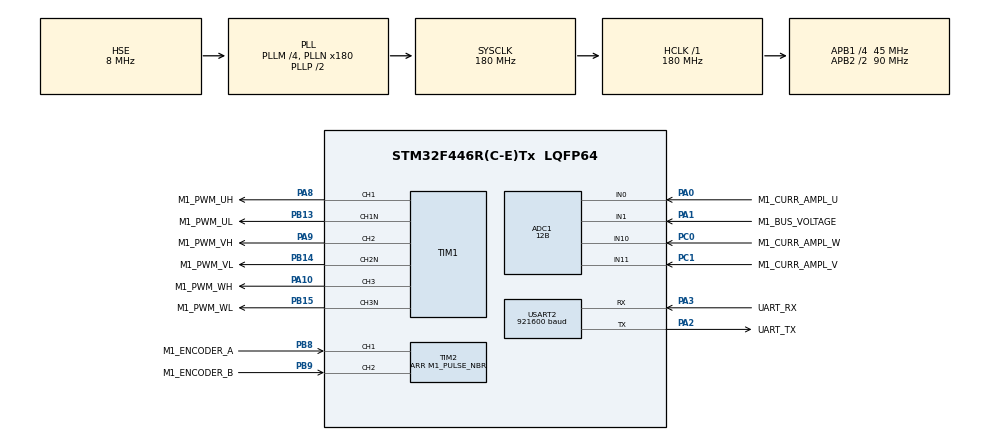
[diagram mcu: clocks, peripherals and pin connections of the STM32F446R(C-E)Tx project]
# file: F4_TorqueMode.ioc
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ADC1.Channel-1\#ChannelInjectedConversion=ADC_CHANNEL_0
ADC1.Channel-1\#ChannelRegularConversion=ADC_CHANNEL_1
ADC1.Channel-2\#ChannelInjectedConversion=ADC_CHANNEL_11
ADC1.Channel-3\#ChannelInjectedConversion=ADC_CHANNEL_10
ADC1.ClockPrescaler=ADC_CLOCK_SYNC_PCLK_DIV4
ADC1.ContinuousConvMode=DISABLE
ADC1.DMAContinuousRequests=DISABLE
ADC1.DataAlign=ADC_DATAALIGN_LEFT
ADC1.DiscontinuousConvMode=DISABLE
ADC1.EOCSelection=ADC_EOC_SINGLE_CONV
ADC1.EnableAnalogWatchDog=false
ADC1.EnableInjectedConversion=ENABLE
ADC1.EnableRegularConversion=ENABLE
ADC1.ExternalTrigConv=ADC_SOFTWARE_START
ADC1.ExternalTrigConvEdge=ADC_EXTERNALTRIGCONVEDGE_NONE
ADC1.ExternalTrigInjecConv=ADC_EXTERNALTRIGINJECCONV_T1_CC4
ADC1.ExternalTrigInjecConvEdge=ADC_EXTERNALTRIGINJECCONVEDGE_RISING
ADC1.InjNumberOfConversion=3
ADC1.InjectedConvMode=None
ADC1.InjectedOffset-1\#ChannelInjectedConversion=0
ADC1.InjectedOffset-2\#ChannelInjectedConversion=0
ADC1.InjectedOffset-3\#ChannelInjectedConversion=0
ADC1.InjectedRank-1\#ChannelInjectedConversion=1
ADC1.InjectedRank-2\#ChannelInjectedConversion=2
ADC1.InjectedRank-3\#ChannelInjectedConversion=3
ADC1.NbrOfConversion=1
ADC1.NbrOfConversionFlag=1
ADC1.Offset-1\#ChannelRegularConversion=0
ADC1.OffsetNumber-1\#ChannelRegularConversion=ADC_OFFSET_NONE
ADC1.Rank-1\#ChannelRegularConversion=1
ADC1.Resolution=ADC_RESOLUTION_12B
ADC1.SamplingTime-1\#ChannelInjectedConversion=ADC_SAMPLETIME_15CYCLES
ADC1.SamplingTime-1\#ChannelRegularConversion=ADC_SAMPLETIME_28CYCLES
ADC1.SamplingTime-2\#ChannelInjectedConversion=ADC_SAMPLETIME_15CYCLES
ADC1.SamplingTime-3\#ChannelInjectedConversion=ADC_SAMPLETIME_15CYCLES
ADC1.ScanConvMode=ENABLE
ADC1.master=1
Dma.Request0=USART2_RX
Dma.Request1=USART2_TX
Dma.USART2_RX.0.Direction=DMA_PERIPH_TO_MEMORY
Dma.USART2_RX.0.FIFOMode=DMA_FIFOMODE_DISABLE
Dma.USART2_RX.0.Instance=DMA1_Stream5
Dma.USART2_RX.0.MemDataAlignment=DMA_MDATAALIGN_BYTE
Dma.USART2_RX.0.MemInc=DMA_MINC_ENABLE
Dma.USART2_RX.0.Mode=DMA_NORMAL
Dma.USART2_RX.0.PeriphDataAlignment=DMA_PDATAALIGN_BYTE
Dma.USART2_RX.0.PeriphInc=DMA_PINC_DISABLE
Dma.USART2_RX.0.Priority=DMA_PRIORITY_LOW
Dma.USART2_TX.1.Direction=DMA_MEMORY_TO_PERIPH
Dma.USART2_TX.1.FIFOMode=DMA_FIFOMODE_DISABLE
Dma.USART2_TX.1.Instance=DMA1_Stream6
Dma.USART2_TX.1.MemDataAlignment=DMA_MDATAALIGN_BYTE
Dma.USART2_TX.1.MemInc=DMA_MINC_ENABLE
Dma.USART2_TX.1.Mode=DMA_NORMAL
Dma.USART2_TX.1.PeriphDataAlignment=DMA_PDATAALIGN_BYTE
Dma.USART2_TX.1.PeriphInc=DMA_PINC_DISABLE
Dma.USART2_TX.1.Priority=DMA_PRIORITY_LOW
ExtraMW=MotorControl
ExtraMW.MotorControl.Config=MotorControl
ExtraMW.MotorControl.Mode=MotorControl
ExtraMW.MotorControl.Root=MCSDK_v6.2.0-Full/MotorControl
ExtraMW.MotorControl.Template=templates
Mcu.Family=STM32F4
Mcu.Name=STM32F446R(C-E)Tx
Mcu.Package=LQFP64
MotorControl.ADC_AHBPERIPH=RCC_AHBPeriph_ADC1
MotorControl.ADC_CLOCK_WB_DIV=1
MotorControl.ADC_PERIPH=ADC1
MotorControl.ADC_REFERENCE_VOLTAGE=3.3
MotorControl.AUXILIARY_SPEED_MEASUREMENT_SELECTION=AUX_STATE_OBSERVER_CORDIC
MotorControl.AUX_STATE_OBSERVER_CORDIC=true
MotorControl.BOARD=NUCLEO-F446RE
MotorControl.BUS_VOLTAGE_READING=true
MotorControl.CCMRAM_ENABLED=false
MotorControl.CLOCK_FREQUENCY=CPU_CLK_180_MHZ
MotorControl.CLOCK_SOURCE=EXTERNAL
MotorControl.CPU_CLK_180_MHZ=true
MotorControl.CTLBOARD_NAME=NUCLEO-F446RE
MotorControl.CUBE_MX_VER=6.6.1
MotorControl.CURRENT_READING_TOPOLOGY=THREE_SHUNT
MotorControl.CURR_SAMPLING_TIME=15
MotorControl.DBG_MCU_LOAD_MEASURE=false
MotorControl.DEBUG_DAC_FUNCTIONALITY_EN=false
MotorControl.DRIVES_NUMBER_SELECTION=SINGLEDRIVE
MotorControl.DRIVE_NUMBER=1
MotorControl.DRIVE_TYPE=FOC
MotorControl.ENCODER=true
MotorControl.ENCODER_AVAILABLE=true
MotorControl.ENCODER_PPR=1024
MotorControl.ENC_A_GPIO_PIN=LL_GPIO_PIN_8
MotorControl.ENC_A_GPIO_PORT=GPIOB
MotorControl.ENC_B_GPIO_PIN=LL_GPIO_PIN_9
MotorControl.ENC_B_GPIO_PORT=GPIOB
MotorControl.ENC_ICx_FILTER=126
MotorControl.ENC_INVERT_SPEED=false
MotorControl.ENC_TIMER_SELECTION=ENC_TIM2
MotorControl.ENC_USE_CH3=false
MotorControl.EXT_CLK_8_MHZ=true
MotorControl.EXT_CLOCK_FREQUENCY=EXT_CLK_8_MHZ
MotorControl.FEEDBACK_NET_FILTERING=false
MotorControl.HALL_SENSORS_AVAILABLE=false
MotorControl.HIGH_SIDE_IDLE_STATE=false
MotorControl.HWV_CS=ThreeShunt_AmplifiedCurrents
MotorControl.HWV_PWM=DrivingHighAndLowSides
MotorControl.HW_COMPLEMENTED_LOW_SIDE=false
MotorControl.HW_DEAD_TIME_NS=1000
MotorControl.IPs=NVIC,RCC,SYS,MotorControl,ADC1,TIM1,TIM2,USART2,DMA
MotorControl.LOW_MEMORY_FOOTPRINT_REG=false
MotorControl.LOW_SIDE_IDLE_STATE=false
MotorControl.LOW_SIDE_SIGNALS_ENABLING=LS_PWM_TIMER
MotorControl.M1_ALIGNMENT_ANGLE_DEG=90
MotorControl.M1_ALIGNMENT_DURATION=700
MotorControl.M1_AMPLIFICATION_GAIN=20
MotorControl.M1_ANGC={0,0,0,0,0,0,0,0}
MotorControl.M1_AUXILIARY_SPEED_SENSOR=STO_CORDIC
MotorControl.M1_BOARD_MAX_CURRENT=15
MotorControl.M1_BUS_VOLTAGE_READING=true
MotorControl.M1_CONSTANT1_D=9205
MotorControl.M1_CONSTANT1_Q=9205
MotorControl.M1_CONSTANT2_QD=12498
MotorControl.M1_CORD_BEMF_CONSISTENCY_GAIN=64
MotorControl.M1_CORD_BEMF_CONSISTENCY_TOL=64
MotorControl.M1_CORD_F1=4096
MotorControl.M1_CORD_F2=16384
MotorControl.M1_CORD_FIFO_DEPTH_01HZ=64
MotorControl.M1_CORD_FIFO_DEPTH_DPP=64
MotorControl.M1_CORD_GAIN1=-3529
MotorControl.M1_CORD_GAIN2=1632
MotorControl.M1_CORD_MAX_ACCEL_DPPP=199
MotorControl.M1_CORD_VARIANCE_THRESHOLD=25
MotorControl.M1_CS_ADC_NUM=1
MotorControl.M1_CS_ADC_PHASE_SHARED=NONE
MotorControl.M1_CS_ADC_U=ADC1
MotorControl.M1_CS_ADC_V=ADC1
MotorControl.M1_CS_ADC_W=ADC1
MotorControl.M1_CS_CHANNEL_U=0
MotorControl.M1_CS_CHANNEL_V=11
MotorControl.M1_CS_CHANNEL_W=10
MotorControl.M1_CURRENT_AMPLIFICATION_TOPO=EXTERNAL
MotorControl.M1_CURRENT_SENSING_TOPO=THREE_SHUNT
MotorControl.M1_CURR_SAMPLING_TIME=15
MotorControl.M1_DBG_OPEN_LOOP_ENABLE=false
MotorControl.M1_DC_CURRENT_RS_MEAS=15
MotorControl.M1_DEFAULT_CONTROL_MODE=STC_TORQUE_MODE
MotorControl.M1_DEFAULT_FLUX_COMPONENT=0
MotorControl.M1_DEFAULT_TARGET_SPEED_RPM=592
MotorControl.M1_DEFAULT_TORQUE_COMPONENT=0
MotorControl.M1_DISCONTINUOUS_PWM=false
MotorControl.M1_DP_TOPOLOGY=NONE
MotorControl.M1_DRIVE_TYPE=FOC
MotorControl.M1_ENCODER_PPR=1024
MotorControl.M1_ENC_AVERAGING_FIFO_DEPTH=16
MotorControl.M1_ENC_A_GPIO_PIN=LL_GPIO_PIN_8
MotorControl.M1_ENC_A_GPIO_PORT=GPIOB
MotorControl.M1_ENC_B_GPIO_PIN=LL_GPIO_PIN_9
MotorControl.M1_ENC_B_GPIO_PORT=GPIOB
MotorControl.M1_ENC_ICx_FILTER=126
MotorControl.M1_ENC_TIMER_SELECTION=ENC_TIM2
MotorControl.M1_ENC_USE_CH3=false
MotorControl.M1_FEED_FORWARD_CURRENT_REG_ENABLING=false
MotorControl.M1_FINAL_I_ALIGNMENT=15
MotorControl.M1_FLUX_WEAKENING_ENABLING=false
MotorControl.M1_FW_KIDIV=32768
MotorControl.M1_FW_KI_GAIN=5000
MotorControl.M1_FW_KPDIV=32768
MotorControl.M1_FW_KP_GAIN=3000
MotorControl.M1_FW_VOLTAGE_REF=985
MotorControl.M1_HALL_PHASE_SHIFT=300
MotorControl.M1_HALL_SENSORS_PLACEMENT=DEGREES_120
MotorControl.M1_HIGH_SIDE_IDLE_STATE=false
MotorControl.M1_HW_DEAD_TIME_NS=1000
MotorControl.M1_ICL_ENABLED=false
MotorControl.M1_ID_DEMAG=-15
MotorControl.M1_IQMAX=15
MotorControl.M1_LDLQ_RATIO=1.000
MotorControl.M1_LOW_SIDE_IDLE_STATE=false
MotorControl.M1_LOW_SIDE_SIGNALS_ENABLING=LS_PWM_TIMER
MotorControl.M1_LS=0.00003
MotorControl.M1_MAX_APPLICATION_SPEED=6000
MotorControl.M1_MAX_MODULATION_INDEX=100
MotorControl.M1_MIN_APPLICATION_SPEED=0
MotorControl.M1_MOTOR_MAX_SPEED_RPM=6000
MotorControl.M1_MOTOR_NAME=MN5008_PlanetGears
MotorControl.M1_MOTOR_RATED_FLUX=0.024129002
MotorControl.M1_MOTOR_VOLTAGE_CONSTANT=6.9
MotorControl.M1_MTPA_ENABLING=false
MotorControl.M1_NOMINAL_BUS_VOLTAGE_V=40
MotorControl.M1_NOMINAL_CURRENT=15
MotorControl.M1_OCP_TOPOLOGY=NONE
MotorControl.M1_OFST={0,0,0,0,0,0,0,0}
MotorControl.M1_ON_OVER_VOLTAGE=TURN_OFF_PWM
MotorControl.M1_OVERMODULATION=false
MotorControl.M1_OVP_THRESHOLD_HIGH=48
MotorControl.M1_OV_VOLTAGE_PROT_ENABLING=true
MotorControl.M1_OV_VOLTAGE_THRESHOLD_V=48
MotorControl.M1_PID_FLUX_KD_DEFAULT=100
MotorControl.M1_PID_FLUX_KI_DEFAULT=1479
MotorControl.M1_PID_FLUX_KP_DEFAULT=1738
MotorControl.M1_PID_SPEED_KD_DEFAULT=0
MotorControl.M1_PID_SPEED_KI_DEFAULT=2301
MotorControl.M1_PID_SPEED_KP_DEFAULT=3447
MotorControl.M1_PID_TORQUE_KD_DEFAULT=100
MotorControl.M1_PID_TORQUE_KI_DEFAULT=1479
MotorControl.M1_PID_TORQUE_KP_DEFAULT=1738
MotorControl.M1_POLE_PAIR_NUM=14
MotorControl.M1_POSITION_CTRL_ENABLING=false
MotorControl.M1_POTENTIOMETER_ENABLE=false
MotorControl.M1_POWERBOARD_NAME=~CUSTOM-DRV8323Rx
MotorControl.M1_PWM_CHARGE_BOOT_CAP_DUTY_CYCLES=0.000
MotorControl.M1_PWM_CHARGE_BOOT_CAP_MS=10
MotorControl.M1_PWM_DRIVER_PN=DRV8323
MotorControl.M1_PWM_FREQUENCY=16000
MotorControl.M1_PWM_TIMER_BRK_IRQ=TIM1_BRK_TIM9
MotorControl.M1_PWM_TIMER_SELECTION=PWM_TIM1
MotorControl.M1_PWM_TIMER_UP_IRQ=TIM1_UP_TIM10
MotorControl.M1_REGULATION_EXECUTION_RATE=1
MotorControl.M1_RS=0.41
MotorControl.M1_RSHUNT=0.007
MotorControl.M1_SEGDIV=0
MotorControl.M1_SHARED_SIGNAL_ENABLE=false
MotorControl.M1_SPD_DIFFERENTIAL_TERM_ENABLING=false
MotorControl.M1_SPEED_LOOP_FREQUENCY_HZ=1000
MotorControl.M1_SPEED_SENSOR=QUAD_ENCODER
MotorControl.M1_SP_KDDIV=16
MotorControl.M1_SP_KIDIV=8192
MotorControl.M1_SP_KPDIV=64
MotorControl.M1_SS_MEAS_ERRORS_BEFORE_FAULTS=3
MotorControl.M1_SW_DEADTIME_NS=850
MotorControl.M1_TEMPERATURE_READING=false
MotorControl.M1_TF_KDDIV=8192
MotorControl.M1_TF_KIDIV=16384
MotorControl.M1_TF_KPDIV=16384
MotorControl.M1_TNOISE_NS=1000
MotorControl.M1_TRISE_NS=1000
MotorControl.M1_UD_VOLTAGE_THRESHOLD_V=6
MotorControl.M1_USE_INTERNAL_OPAMP=false
MotorControl.M1_UV_VOLTAGE_PROT_ENABLING=true
MotorControl.M1_VBUS_ADC=ADC1
MotorControl.M1_VBUS_ADC_SAMPLING_TIME=28
MotorControl.M1_VBUS_CHANNEL=ADC_CHANNEL_1
MotorControl.M1_VBUS_PARTITIONING_FACTOR=0.052164840897235255
MotorControl.MAX_READABLE_CURRENT=11.786
MotorControl.MCPA_OVER_UART_A_STREAM=10
MotorControl.MCP_ASPEP_OVER_UART=true
MotorControl.MCP_ASYNC_EN=true
MotorControl.MCP_ASYNC_OVER_ASPEP_EN=true
MotorControl.MCP_ASYNC_OVER_UART_A_EN=true
MotorControl.MCP_DMACH_RX_UART_A=5
MotorControl.MCP_DMACH_TX_UART_A=6
MotorControl.MCP_DMA_RX_UART_A=DMA1
MotorControl.MCP_DMA_TX_UART_A=DMA1
MotorControl.MCP_EN=true
MotorControl.MCP_IRQ_HANDLER_DMA_RX_UART_A=DMA1_Stream5_IRQHandler
MotorControl.MCP_IRQ_HANDLER_UART_A=USART2_IRQHandler
MotorControl.MCP_OVER_ASPEP_EN=true
MotorControl.MCP_OVER_STLNK_EN=false
MotorControl.MCP_OVER_UART_A_EN=true
MotorControl.MCP_OVER_UART_B_EN=false
MotorControl.MCP_RX_SYNC_PAYLOAD_MAX=128
MotorControl.MCP_TX_ASYNC_PAYLOAD_MAX_UART_A=2048
MotorControl.MCP_TX_SYNC_PAYLOAD_MAX=128
MotorControl.MCU=STM32F446RE
MotorControl.MCU_FAMILY=STM32F4
MotorControl.MCU_LINE=STM32F446
MotorControl.MCU_NAME=STM32F446R(C-E)Tx
MotorControl.MCU_PACKAGE=LQFP64
MotorControl.MCU_TYPE=STM32F446RE
MotorControl.MCU_USERNAME=STM32F446RETx
MotorControl.MC_WORKBENCH_VERSION=6.2.0
MotorControl.MOTOR_PROFILER=false
MotorControl.MOTOR_TYPE=PMSM
MotorControl.ON_OVER_VOLTAGE=TURN_OFF_PWM
MotorControl.OV_VOLTAGE_PROT_ENABLING=true
MotorControl.PHASE_UH_GPIO_PIN=LL_GPIO_PIN_8
MotorControl.PHASE_UH_GPIO_PORT=GPIOA
MotorControl.PHASE_UH_POLARITY=H_ACTIVE_HIGH
MotorControl.PHASE_UL_GPIO_PIN=LL_GPIO_PIN_13
MotorControl.PHASE_UL_GPIO_PORT=GPIOB
MotorControl.PHASE_UL_POLARITY=L_ACTIVE_HIGH
MotorControl.PHASE_U_CURR_ADC=ADC1
MotorControl.PHASE_U_CURR_CHANNEL=ADC_CHANNEL_0
MotorControl.PHASE_U_GPIO_PIN=LL_GPIO_PIN_0
MotorControl.PHASE_U_GPIO_PORT=GPIOA
MotorControl.PHASE_VH_GPIO_PIN=LL_GPIO_PIN_9
MotorControl.PHASE_VH_GPIO_PORT=GPIOA
MotorControl.PHASE_VH_POLARITY=H_ACTIVE_HIGH
MotorControl.PHASE_VL_GPIO_PIN=LL_GPIO_PIN_14
MotorControl.PHASE_VL_GPIO_PORT=GPIOB
MotorControl.PHASE_VL_POLARITY=L_ACTIVE_HIGH
MotorControl.PHASE_V_CURR_ADC=ADC1
MotorControl.PHASE_V_CURR_CHANNEL=ADC_CHANNEL_11
MotorControl.PHASE_V_GPIO_PIN=LL_GPIO_PIN_1
MotorControl.PHASE_V_GPIO_PORT=GPIOC
MotorControl.PHASE_WH_GPIO_PIN=LL_GPIO_PIN_10
MotorControl.PHASE_WH_GPIO_PORT=GPIOA
MotorControl.PHASE_WH_POLARITY=H_ACTIVE_HIGH
MotorControl.PHASE_WL_GPIO_PIN=LL_GPIO_PIN_15
MotorControl.PHASE_WL_GPIO_PORT=GPIOB
MotorControl.PHASE_WL_POLARITY=L_ACTIVE_HIGH
MotorControl.PHASE_W_CURR_ADC=ADC1
MotorControl.PHASE_W_CURR_CHANNEL=ADC_CHANNEL_10
MotorControl.PHASE_W_GPIO_PIN=LL_GPIO_PIN_0
MotorControl.PHASE_W_GPIO_PORT=GPIOC
MotorControl.POTENTIOMETER_READING=false
MotorControl.PWM_FREQUENCY=16000
MotorControl.PWM_TIMER_SELECTION=PWM_TIM1
MotorControl.REGULATION_EXECUTION_RATE=1
MotorControl.RTOS=NONE
MotorControl.R_BRAKE_SWITCH_OFF_THRES_V=38
MotorControl.SINGLEDRIVE=true
MotorControl.SPD_DIFFERENTIAL_TERM_ENABLING=false
MotorControl.SPEED_SENSOR_SELECTION=ENCODER
MotorControl.START_STOP_BTN=false
MotorControl.STM32F446RE=true
MotorControl.SW_DEADTIME_NS=850
MotorControl.TEMPERATURE_READING=false
MotorControl.TFDIFFERENTIAL_TERM_ENABLING=false
MotorControl.THREE_SHUNT=true
MotorControl.TRISE_NS=1000
MotorControl.USART_RX_GPIO_PIN=LL_GPIO_PIN_3
MotorControl.USART_RX_GPIO_PORT=GPIOA
MotorControl.USART_SELECTION=USE_USART2
MotorControl.USART_SELECTION_A=USART2
MotorControl.USART_SPEED=921600
MotorControl.USART_TX_GPIO_PIN=LL_GPIO_PIN_2
MotorControl.USART_TX_GPIO_PORT=GPIOA
MotorControl.USE_3OPAMPS=false
MotorControl.USE_INTERNAL_OPAMP=false
MotorControl.UV_VOLTAGE_PROT_ENABLING=true
MotorControl.VBUS_ADC=ADC1
MotorControl.VBUS_ADC_SAMPLING_TIME=28
MotorControl.VBUS_CHANNEL=ADC_CHANNEL_1
MotorControl.VBUS_GPIO_PIN=LL_GPIO_PIN_1
MotorControl.VBUS_GPIO_PORT=GPIOA
MotorControl.WB_UI_CORD_BEMF_QUALITY_FACTOR=0.018
MotorControl.WB_UI_CORD_MAX_APPLICATION_ACC=6000
MotorControl.WB_UI_CUTOFF_FREQUENCY=6000
MotorControl.WB_UI_ENCODER_HAS_INDEX_PIN=true
MotorControl.WB_UI_FLUX_TARGET=0
MotorControl.WB_UI_FRICTION=11.84
MotorControl.WB_UI_INERTIA=2.27
MotorControl.WB_UI_MAGNETIC_STRUCTURE=SM-PMSM
MotorControl.WB_UI_MAX_CURRENT=15
MotorControl.WB_UI_MAX_NOMINAL_DC_VOLTAGE=40
MotorControl.WB_UI_MOTOR_DESCRIPTION=Motor profile within gearbox housing
MotorControl.WB_UI_PW_BOARD_MAX_RATED_CURRENT=15
MotorControl.WB_UI_PW_BOARD_MAX_VOLTAGE=60
MotorControl.WB_UI_PW_BOARD_MIN_VOLTAGE=6
MotorControl.WB_UI_VPOL=1.65
MotorControl.WB_to_Mx_template_version=23-09-08
MotorControl.WB_to_Mx_version=6.2.0
NVIC.ADC_IRQn=true\:2\:0\:true\:true\:false\:3\:false\:true\:true
NVIC.DMA1_Stream5_IRQn=true\:3\:0\:true\:true\:false\:2\:true\:true\:true
NVIC.PriorityGroup=NVIC_PRIORITYGROUP_3
NVIC.TIM1_BRK_TIM9_IRQn=true\:4\:1\:false\:true\:false\:5\:true\:true\:true
NVIC.TIM1_UP_TIM10_IRQn=true\:0\:0\:false\:true\:false\:4\:true\:true\:true
NVIC.TIM2_IRQn=true\:3\:0\:false\:true\:false\:6\:true\:true\:true
NVIC.USART2_IRQn=true\:3\:1\:true\:true\:false\:1\:true\:true\:true
PA0-WKUP.GPIO_Label=M1_CURR_AMPL_U
PA0-WKUP.Signal=ADCx_IN0
PA1.GPIO_Label=M1_BUS_VOLTAGE
PA1.Signal=ADCx_IN1
PA10.GPIO_Label=M1_PWM_WH
PA10.GPIO_PuPd=GPIO_PULLDOWN
PA10.GPIO_Speed=GPIO_SPEED_FREQ_HIGH
PA10.Signal=S_TIM1_CH3
PA2.GPIO_Label=UART_TX
PA2.GPIO_Mode=GPIO_MODE_AF_PP
PA2.GPIO_PuPd=GPIO_NOPULL
PA2.GPIO_Speed=GPIO_SPEED_FREQ_LOW
PA2.Mode=Asynchronous
PA2.Signal=USART2_TX
PA3.GPIO_Label=UART_RX
PA3.GPIO_Mode=GPIO_MODE_AF_PP
PA3.GPIO_PuPd=GPIO_NOPULL
PA3.GPIO_Speed=GPIO_SPEED_FREQ_LOW
PA3.Mode=Asynchronous
PA3.Signal=USART2_RX
PA8.GPIO_Label=M1_PWM_UH
PA8.GPIO_PuPd=GPIO_PULLDOWN
PA8.GPIO_Speed=GPIO_SPEED_FREQ_HIGH
PA8.Signal=S_TIM1_CH1
PA9.GPIO_Label=M1_PWM_VH
PA9.GPIO_PuPd=GPIO_PULLDOWN
PA9.GPIO_Speed=GPIO_SPEED_FREQ_HIGH
PA9.Signal=S_TIM1_CH2
PB13.GPIO_Label=M1_PWM_UL
PB13.GPIO_PuPd=GPIO_PULLDOWN
PB13.GPIO_Speed=GPIO_SPEED_FREQ_HIGH
PB13.Mode=PWM Generation1 CH1 CH1N
PB13.Signal=TIM1_CH1N
PB14.GPIO_Label=M1_PWM_VL
PB14.GPIO_PuPd=GPIO_PULLDOWN
PB14.GPIO_Speed=GPIO_SPEED_FREQ_HIGH
PB14.Mode=PWM Generation2 CH2 CH2N
PB14.Signal=TIM1_CH2N
PB15.GPIO_Label=M1_PWM_WL
PB15.GPIO_PuPd=GPIO_PULLDOWN
PB15.GPIO_Speed=GPIO_SPEED_FREQ_HIGH
PB15.Mode=PWM Generation3 CH3 CH3N
PB15.Signal=TIM1_CH3N
PB8.GPIO_Label=M1_ENCODER_A
PB8.Signal=S_TIM2_CH1_ETR
PB9.GPIO_Label=M1_ENCODER_B
PB9.Signal=S_TIM2_CH2
PC0.GPIO_Label=M1_CURR_AMPL_W
PC0.Signal=ADCx_IN10
PC1.GPIO_Label=M1_CURR_AMPL_V
PC1.Signal=ADCx_IN11
PH0-OSC_IN.Mode=HSE-External-Oscillator
PH0-OSC_IN.Signal=RCC_OSC_IN
PH1-OSC_OUT.Mode=HSE-External-Oscillator
PH1-OSC_OUT.Signal=RCC_OSC_OUT
ProjectManager.HeapSize=0x200
ProjectManager.StackSize=0x400
ProjectManager.TargetToolchain=STM32CubeIDE
RCC.AHBFreq_Value=180000000
RCC.APB1CLKDivider=RCC_HCLK_DIV4
RCC.APB1Freq_Value=45000000
RCC.APB1TimFreq_Value=90000000
RCC.APB2CLKDivider=RCC_HCLK_DIV2
RCC.APB2Freq_Value=90000000
RCC.APB2TimFreq_Value=180000000
RCC.CortexFreq_Value=180000000
RCC.HCLKFreq_Value=180000000
RCC.HSE_VALUE=8000000
RCC.PLLM=4
RCC.PLLN=180
RCC.PLLSourceVirtual=RCC_PLLSOURCE_HSE
RCC.PREFETCH_ENABLE=1
RCC.SYSCLKFreq_VALUE=180000000
RCC.SYSCLKSource=RCC_SYSCLKSOURCE_PLLCLK
RCC.USBFreq_Value=180000000
RCC.VCOOutputFreq_Value=360000000
SH.ADCx_IN0.0=ADC1_IN0,IN0
SH.ADCx_IN1.0=ADC1_IN1,IN1
SH.ADCx_IN10.0=ADC1_IN10,IN10
SH.ADCx_IN11.0=ADC1_IN11,IN11
SH.S_TIM1_CH1.0=TIM1_CH1,PWM Generation1 CH1 CH1N
SH.S_TIM1_CH2.0=TIM1_CH2,PWM Generation2 CH2 CH2N
SH.S_TIM1_CH3.0=TIM1_CH3,PWM Generation3 CH3 CH3N
SH.S_TIM2_CH1_ETR.0=TIM2_CH1,Encoder_Interface
SH.S_TIM2_CH2.0=TIM2_CH2,Encoder_Interface
TIM1.AutoReloadPreload=TIM_AUTORELOAD_PRELOAD_DISABLE
TIM1.AutomaticOutput=TIM_AUTOMATICOUTPUT_DISABLE
TIM1.BreakPolarity=TIM_BREAKPOLARITY_LOW
TIM1.BreakState=TIM_BREAK_DISABLE
TIM1.Channel-PWM\ Generation1\ CH1\ CH1N=TIM_CHANNEL_1
TIM1.Channel-PWM\ Generation2\ CH2\ CH2N=TIM_CHANNEL_2
TIM1.Channel-PWM\ Generation3\ CH3\ CH3N=TIM_CHANNEL_3
TIM1.Channel-PWM\ Generation4\ No\ Output=TIM_CHANNEL_4
TIM1.ClearInputSource=TIM_CLEARINPUTSOURCE_NONE
TIM1.ClockDivision=TIM_CLOCKDIVISION_DIV2
TIM1.CounterMode=TIM_COUNTERMODE_CENTERALIGNED1
TIM1.DeadTime=((DEAD_TIME_COUNTS) / 2)
TIM1.LockLevel=TIM_LOCKLEVEL_OFF
TIM1.OC1Preload_PWM=ENABLE
TIM1.OC2Preload_PWM=ENABLE
TIM1.OC3Preload_PWM=ENABLE
TIM1.OC4Preload_PWM=ENABLE
TIM1.OCIdleState_1=TIM_OCIDLESTATE_RESET
TIM1.OCIdleState_2=TIM_OCIDLESTATE_RESET
TIM1.OCIdleState_3=TIM_OCIDLESTATE_RESET
TIM1.OCIdleState_4=TIM_OCIDLESTATE_RESET
TIM1.OCMode_PWM-PWM\ Generation1\ CH1\ CH1N=TIM_OCMODE_PWM1
TIM1.OCMode_PWM-PWM\ Generation2\ CH2\ CH2N=TIM_OCMODE_PWM1
TIM1.OCMode_PWM-PWM\ Generation3\ CH3\ CH3N=TIM_OCMODE_PWM1
TIM1.OCMode_PWM-PWM\ Generation4\ No\ Output=TIM_OCMODE_PWM2
TIM1.OCNIdleState_1=TIM_OCNIDLESTATE_RESET
TIM1.OCNIdleState_2=TIM_OCNIDLESTATE_RESET
TIM1.OCNIdleState_3=TIM_OCNIDLESTATE_RESET
TIM1.OCNPolarity_1=TIM_OCNPOLARITY_HIGH
TIM1.OCNPolarity_2=TIM_OCNPOLARITY_HIGH
TIM1.OCNPolarity_3=TIM_OCNPOLARITY_HIGH
TIM1.OCPolarity_1=TIM_OCPOLARITY_HIGH
TIM1.OCPolarity_2=TIM_OCPOLARITY_HIGH
TIM1.OCPolarity_3=TIM_OCPOLARITY_HIGH
TIM1.OCPolarity_4=TIM_OCPOLARITY_HIGH
TIM1.OffStateIDLEMode=TIM_OSSI_ENABLE
TIM1.OffStateRunMode=TIM_OSSR_ENABLE
TIM1.Period=((PWM_PERIOD_CYCLES) / 2)
TIM1.Prescaler=((TIM_CLOCK_DIVIDER) - 1)
TIM1.Pulse-PWM\ Generation1\ CH1\ CH1N=((PWM_PERIOD_CYCLES) / 4)
TIM1.Pulse-PWM\ Generation2\ CH2\ CH2N=((PWM_PERIOD_CYCLES) / 4)
TIM1.Pulse-PWM\ Generation3\ CH3\ CH3N=((PWM_PERIOD_CYCLES) / 4)
TIM1.Pulse-PWM\ Generation4\ No\ Output=(((PWM_PERIOD_CYCLES) / 2) - (HTMIN))
TIM1.RepetitionCounter=(REP_COUNTER)
TIM1.TIM_MasterOutputTrigger=TIM_TRGO_RESET
TIM1.TIM_MasterSlaveMode=TIM_MASTERSLAVEMODE_DISABLE
TIM2.EncoderMode=TIM_ENCODERMODE_TI12
TIM2.IC1Filter=M1_ENC_IC_FILTER
TIM2.IC1Polarity=TIM_ICPOLARITY_RISING
TIM2.IC2Filter=M1_ENC_IC_FILTER
TIM2.IC2Polarity=TIM_ICPOLARITY_RISING
TIM2.Period=M1_PULSE_NBR
USART2.BaudRate=921600
USART2.VirtualMode=VM_ASYNC
USART2.VirtualMode-Asynchronous=VM_ASYNC
USART2.WordLength=WORDLENGTH_8B
VP_MotorControl_MC_ENABLED.Mode=Enabled
VP_TIM1_VS_ClockSourceITR.Mode=TriggerSource_ITR1
VP_TIM1_VS_ControllerModeTrigger.Mode=Trigger Mode
VP_TIM1_VS_no_output4.Mode=PWM Generation4 No Output
board=custom

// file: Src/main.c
/* USER CODE BEGIN Header */
/**
  ******************************************************************************
  * @file           : main.c
  * @brief          : Main program body
  ******************************************************************************
  * @attention
  *
  * Copyright (c) 2024 STMicroelectronics.
  * All rights reserved.
  *
  * This software is licensed under terms that can be found in the LICENSE file
  * in the root directory of this software component.
  * If no LICENSE file comes with this software, it is provided AS-IS.
  *
  ******************************************************************************
  */
/* USER CODE END Header */
#include "main.h"

/* USER CODE BEGIN Includes */
#include <stdint.h>
/* USER CODE END Includes */

ADC_HandleTypeDef hadc1;

TIM_HandleTypeDef htim1;
TIM_HandleTypeDef htim2;

UART_HandleTypeDef huart2;
DMA_HandleTypeDef hdma_usart2_rx;
DMA_HandleTypeDef hdma_usart2_tx;

void SystemClock_Config(void);
static void MX_GPIO_Init(void);
static void MX_DMA_Init(void);
static void MX_ADC1_Init(void);
static void MX_TIM1_Init(void);
static void MX_TIM2_Init(void);
static void MX_USART2_UART_Init(void);
static void MX_NVIC_Init(void);

int main(void)
{

  /* MCU Configuration--------------------------------------------------------*/

  /* Reset of all peripherals, Initializes the Flash interface and the Systick. */
  HAL_Init();

  /* Configure the system clock */
  SystemClock_Config();

  /* Initialize all configured peripherals */
  MX_GPIO_Init();
  MX_DMA_Init();
  MX_ADC1_Init();
  MX_TIM1_Init();
  MX_TIM2_Init();
  MX_USART2_UART_Init();
  MX_MotorControl_Init();

  /* Initialize interrupts */
  MX_NVIC_Init();
  /* USER CODE BEGIN 2 */
  HAL_GPIO_WritePin(GPIOC, GPIO_PIN_6, GPIO_PIN_RESET);   //B
  HAL_GPIO_WritePin(GPIOC, GPIO_PIN_7, GPIO_PIN_RESET); //G
  HAL_GPIO_WritePin(GPIOC, GPIO_PIN_8, GPIO_PIN_SET);   //R

  HAL_GPIO_WritePin(GPIOC, GPIO_PIN_14, GPIO_PIN_SET);   // DRV Enable
  /* USER CODE END 2 */

  /* Infinite loop */
  while (1)
  {

  }
}

void SystemClock_Config(void)
{
  RCC_OscInitTypeDef RCC_OscInitStruct = {0};
  RCC_ClkInitTypeDef RCC_ClkInitStruct = {0};

  /** Configure the main internal regulator output voltage
  */
  __HAL_RCC_PWR_CLK_ENABLE();
  __HAL_PWR_VOLTAGESCALING_CONFIG(PWR_REGULATOR_VOLTAGE_SCALE1);

  /** Initializes the RCC Oscillators according to the specified parameters
  * in the RCC_OscInitTypeDef structure.
  */
  RCC_OscInitStruct.OscillatorType = RCC_OSCILLATORTYPE_HSE;
  RCC_OscInitStruct.HSEState = RCC_HSE_ON;
  RCC_OscInitStruct.PLL.PLLState = RCC_PLL_ON;
  RCC_OscInitStruct.PLL.PLLSource = RCC_PLLSOURCE_HSE;
  RCC_OscInitStruct.PLL.PLLM = 4;
  RCC_OscInitStruct.PLL.PLLN = 180;
  RCC_OscInitStruct.PLL.PLLP = RCC_PLLP_DIV2;
  RCC_OscInitStruct.PLL.PLLQ = 2;
  RCC_OscInitStruct.PLL.PLLR = 2;
  if (HAL_RCC_OscConfig(&RCC_OscInitStruct) != HAL_OK)
  {
    Error_Handler();
  }

  /** Activate the Over-Drive mode
  */
  if (HAL_PWREx_EnableOverDrive() != HAL_OK)
  {
    Error_Handler();
  }

  /** Initializes the CPU, AHB and APB buses clocks
  */
  RCC_ClkInitStruct.ClockType = RCC_CLOCKTYPE_HCLK|RCC_CLOCKTYPE_SYSCLK
                              |RCC_CLOCKTYPE_PCLK1|RCC_CLOCKTYPE_PCLK2;
  RCC_ClkInitStruct.SYSCLKSource = RCC_SYSCLKSOURCE_PLLCLK;
  RCC_ClkInitStruct.AHBCLKDivider = RCC_SYSCLK_DIV1;
  RCC_ClkInitStruct.APB1CLKDivider = RCC_HCLK_DIV4;
  RCC_ClkInitStruct.APB2CLKDivider = RCC_HCLK_DIV2;

  if (HAL_RCC_ClockConfig(&RCC_ClkInitStruct, FLASH_LATENCY_5) != HAL_OK)
  {
    Error_Handler();
  }
}

/**
  * @brief NVIC Configuration.
  * @retval None
  */
static void MX_NVIC_Init(void)
{
  /* USART2_IRQn interrupt configuration */
  HAL_NVIC_SetPriority(USART2_IRQn, 3, 1);
  HAL_NVIC_EnableIRQ(USART2_IRQn);
  /* DMA1_Stream5_IRQn interrupt configuration */
  HAL_NVIC_SetPriority(DMA1_Stream5_IRQn, 3, 0);
  HAL_NVIC_EnableIRQ(DMA1_Stream5_IRQn);
  /* ADC_IRQn interrupt configuration */
  HAL_NVIC_SetPriority(ADC_IRQn, 2, 0);
  HAL_NVIC_EnableIRQ(ADC_IRQn);
  /* TIM1_UP_TIM10_IRQn interrupt configuration */
  HAL_NVIC_SetPriority(TIM1_UP_TIM10_IRQn, 0, 0);
  HAL_NVIC_EnableIRQ(TIM1_UP_TIM10_IRQn);
  /* TIM1_BRK_TIM9_IRQn interrupt configuration */
  HAL_NVIC_SetPriority(TIM1_BRK_TIM9_IRQn, 4, 1);
  HAL_NVIC_EnableIRQ(TIM1_BRK_TIM9_IRQn);
  /* TIM2_IRQn interrupt configuration */
  HAL_NVIC_SetPriority(TIM2_IRQn, 3, 0);
  HAL_NVIC_EnableIRQ(TIM2_IRQn);
}

static void MX_ADC1_Init(void)
{

  ADC_InjectionConfTypeDef sConfigInjected = {0};
  ADC_ChannelConfTypeDef sConfig = {0};

  /** Configure the global features of the ADC (Clock, Resolution, Data Alignment and number of conversion)
  */
  hadc1.Instance = ADC1;
  hadc1.Init.ClockPrescaler = ADC_CLOCK_SYNC_PCLK_DIV4;
  hadc1.Init.Resolution = ADC_RESOLUTION_12B;
  hadc1.Init.ScanConvMode = ENABLE;
  hadc1.Init.ContinuousConvMode = DISABLE;
  hadc1.Init.DiscontinuousConvMode = DISABLE;
  hadc1.Init.ExternalTrigConvEdge = ADC_EXTERNALTRIGCONVEDGE_NONE;
  hadc1.Init.ExternalTrigConv = ADC_SOFTWARE_START;
  hadc1.Init.DataAlign = ADC_DATAALIGN_LEFT;
  hadc1.Init.NbrOfConversion = 1;
  hadc1.Init.DMAContinuousRequests = DISABLE;
  hadc1.Init.EOCSelection = ADC_EOC_SINGLE_CONV;
  if (HAL_ADC_Init(&hadc1) != HAL_OK)
  {
    Error_Handler();
  }

  /** Configures for the selected ADC injected channel its corresponding rank in the sequencer and its sample time
  */
  sConfigInjected.InjectedChannel = ADC_CHANNEL_0;
  sConfigInjected.InjectedRank = 1;
  sConfigInjected.InjectedNbrOfConversion = 3;
  sConfigInjected.InjectedSamplingTime = ADC_SAMPLETIME_15CYCLES;
  sConfigInjected.ExternalTrigInjecConvEdge = ADC_EXTERNALTRIGINJECCONVEDGE_RISING;
  sConfigInjected.ExternalTrigInjecConv = ADC_EXTERNALTRIGINJECCONV_T1_CC4;
  sConfigInjected.AutoInjectedConv = DISABLE;
  sConfigInjected.InjectedDiscontinuousConvMode = DISABLE;
  sConfigInjected.InjectedOffset = 0;
  if (HAL_ADCEx_InjectedConfigChannel(&hadc1, &sConfigInjected) != HAL_OK)
  {
    Error_Handler();
  }

  /** Configures for the selected ADC injected channel its corresponding rank in the sequencer and its sample time
  */
  sConfigInjected.InjectedChannel = ADC_CHANNEL_11;
  sConfigInjected.InjectedRank = 2;
  if (HAL_ADCEx_InjectedConfigChannel(&hadc1, &sConfigInjected) != HAL_OK)
  {
    Error_Handler();
  }

  /** Configures for the selected ADC injected channel its corresponding rank in the sequencer and its sample time
  */
  sConfigInjected.InjectedChannel = ADC_CHANNEL_10;
  sConfigInjected.InjectedRank = 3;
  if (HAL_ADCEx_InjectedConfigChannel(&hadc1, &sConfigInjected) != HAL_OK)
  {
    Error_Handler();
  }

  /** Configure for the selected ADC regular channel its corresponding rank in the sequencer and its sample time.
  */
  sConfig.Channel = ADC_CHANNEL_1;
  sConfig.Rank = 1;
  sConfig.SamplingTime = ADC_SAMPLETIME_28CYCLES;
  sConfig.Offset = 0;

  if (HAL_ADC_ConfigChannel(&hadc1, &sConfig) != HAL_OK)
  {
    Error_Handler();
  }

}

static void MX_TIM1_Init(void)
{

  TIM_SlaveConfigTypeDef sSlaveConfig = {0};
  TIM_MasterConfigTypeDef sMasterConfig = {0};
  TIM_OC_InitTypeDef sConfigOC = {0};
  TIM_BreakDeadTimeConfigTypeDef sBreakDeadTimeConfig = {0};

  htim1.Instance = TIM1;
  htim1.Init.Prescaler = ((TIM_CLOCK_DIVIDER) - 1);
  htim1.Init.CounterMode = TIM_COUNTERMODE_CENTERALIGNED1;
  htim1.Init.Period = ((PWM_PERIOD_CYCLES) / 2);
  htim1.Init.ClockDivision = TIM_CLOCKDIVISION_DIV2;
  htim1.Init.RepetitionCounter = (REP_COUNTER);
  htim1.Init.AutoReloadPreload = TIM_AUTORELOAD_PRELOAD_DISABLE;
  if (HAL_TIM_Base_Init(&htim1) != HAL_OK)
  {
    Error_Handler();
  }
  if (HAL_TIM_PWM_Init(&htim1) != HAL_OK)
  {
    Error_Handler();
  }
  sSlaveConfig.SlaveMode = TIM_SLAVEMODE_TRIGGER;
  sSlaveConfig.InputTrigger = TIM_TS_ITR1;
  if (HAL_TIM_SlaveConfigSynchro(&htim1, &sSlaveConfig) != HAL_OK)
  {
    Error_Handler();
  }
  sMasterConfig.MasterOutputTrigger = TIM_TRGO_RESET;
  sMasterConfig.MasterSlaveMode = TIM_MASTERSLAVEMODE_DISABLE;
  if (HAL_TIMEx_MasterConfigSynchronization(&htim1, &sMasterConfig) != HAL_OK)
  {
    Error_Handler();
  }
  sConfigOC.OCMode = TIM_OCMODE_PWM1;
  sConfigOC.Pulse = ((PWM_PERIOD_CYCLES) / 4);
  sConfigOC.OCPolarity = TIM_OCPOLARITY_HIGH;
  sConfigOC.OCNPolarity = TIM_OCNPOLARITY_HIGH;
  sConfigOC.OCFastMode = TIM_OCFAST_DISABLE;
  sConfigOC.OCIdleState = TIM_OCIDLESTATE_RESET;
  sConfigOC.OCNIdleState = TIM_OCNIDLESTATE_RESET;
  if (HAL_TIM_PWM_ConfigChannel(&htim1, &sConfigOC, TIM_CHANNEL_1) != HAL_OK)
  {
    Error_Handler();
  }
  if (HAL_TIM_PWM_ConfigChannel(&htim1, &sConfigOC, TIM_CHANNEL_2) != HAL_OK)
  {
    Error_Handler();
  }
  if (HAL_TIM_PWM_ConfigChannel(&htim1, &sConfigOC, TIM_CHANNEL_3) != HAL_OK)
  {
    Error_Handler();
  }
  sConfigOC.OCMode = TIM_OCMODE_PWM2;
  sConfigOC.Pulse = (((PWM_PERIOD_CYCLES) / 2) - (HTMIN));
  if (HAL_TIM_PWM_ConfigChannel(&htim1, &sConfigOC, TIM_CHANNEL_4) != HAL_OK)
  {
    Error_Handler();
  }
  sBreakDeadTimeConfig.OffStateRunMode = TIM_OSSR_ENABLE;
  sBreakDeadTimeConfig.OffStateIDLEMode = TIM_OSSI_ENABLE;
  sBreakDeadTimeConfig.LockLevel = TIM_LOCKLEVEL_OFF;
  sBreakDeadTimeConfig.DeadTime = ((DEAD_TIME_COUNTS) / 2);
  sBreakDeadTimeConfig.BreakState = TIM_BREAK_DISABLE;
  sBreakDeadTimeConfig.BreakPolarity = TIM_BREAKPOLARITY_LOW;
  sBreakDeadTimeConfig.AutomaticOutput = TIM_AUTOMATICOUTPUT_DISABLE;
  if (HAL_TIMEx_ConfigBreakDeadTime(&htim1, &sBreakDeadTimeConfig) != HAL_OK)
  {
    Error_Handler();
  }
  HAL_TIM_MspPostInit(&htim1);

}

static void MX_TIM2_Init(void)
{

  TIM_Encoder_InitTypeDef sConfig = {0};
  TIM_MasterConfigTypeDef sMasterConfig = {0};

  htim2.Instance = TIM2;
  htim2.Init.Prescaler = 0;
  htim2.Init.CounterMode = TIM_COUNTERMODE_UP;
  htim2.Init.Period = M1_PULSE_NBR;
  htim2.Init.ClockDivision = TIM_CLOCKDIVISION_DIV1;
  htim2.Init.AutoReloadPreload = TIM_AUTORELOAD_PRELOAD_DISABLE;
  sConfig.EncoderMode = TIM_ENCODERMODE_TI12;
  sConfig.IC1Polarity = TIM_ICPOLARITY_RISING;
  sConfig.IC1Selection = TIM_ICSELECTION_DIRECTTI;
  sConfig.IC1Prescaler = TIM_ICPSC_DIV1;
  sConfig.IC1Filter = M1_ENC_IC_FILTER;
  sConfig.IC2Polarity = TIM_ICPOLARITY_RISING;
  sConfig.IC2Selection = TIM_ICSELECTION_DIRECTTI;
  sConfig.IC2Prescaler = TIM_ICPSC_DIV1;
  sConfig.IC2Filter = M1_ENC_IC_FILTER;
  if (HAL_TIM_Encoder_Init(&htim2, &sConfig) != HAL_OK)
  {
    Error_Handler();
  }
  sMasterConfig.MasterOutputTrigger = TIM_TRGO_RESET;
  sMasterConfig.MasterSlaveMode = TIM_MASTERSLAVEMODE_DISABLE;
  if (HAL_TIMEx_MasterConfigSynchronization(&htim2, &sMasterConfig) != HAL_OK)
  {
    Error_Handler();
  }

}

static void MX_USART2_UART_Init(void)
{

  huart2.Instance = USART2;
  huart2.Init.BaudRate = 921600;
  huart2.Init.WordLength = UART_WORDLENGTH_8B;
  huart2.Init.StopBits = UART_STOPBITS_1;
  huart2.Init.Parity = UART_PARITY_NONE;
  huart2.Init.Mode = UART_MODE_TX_RX;
  huart2.Init.HwFlowCtl = UART_HWCONTROL_NONE;
  huart2.Init.OverSampling = UART_OVERSAMPLING_16;
  if (HAL_UART_Init(&huart2) != HAL_OK)
  {
    Error_Handler();
  }

}

static void MX_DMA_Init(void)
{

  /* DMA controller clock enable */
  __HAL_RCC_DMA1_CLK_ENABLE();

}

static void MX_GPIO_Init(void)
{

  /* GPIO Ports Clock Enable */
  __HAL_RCC_GPIOH_CLK_ENABLE();
  __HAL_RCC_GPIOC_CLK_ENABLE();
  __HAL_RCC_GPIOA_CLK_ENABLE();
  __HAL_RCC_GPIOB_CLK_ENABLE();

}

void Error_Handler(void)
{
  __disable_irq();
  while (1)
  {
  }
}
